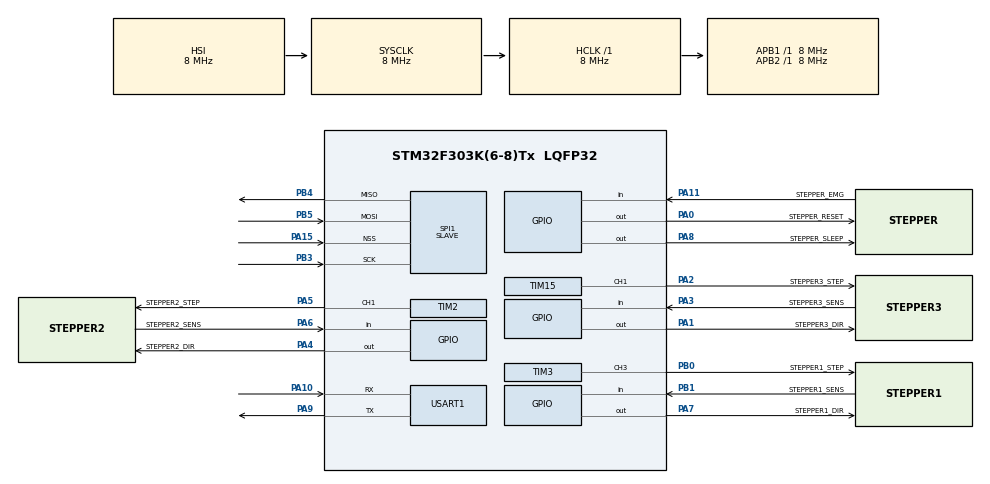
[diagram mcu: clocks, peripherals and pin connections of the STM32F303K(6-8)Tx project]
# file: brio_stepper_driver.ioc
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Dma.Request0=SPI1_RX
Dma.Request1=SPI1_TX
Dma.SPI1_RX.0.Direction=DMA_PERIPH_TO_MEMORY
Dma.SPI1_RX.0.Instance=DMA1_Channel2
Dma.SPI1_RX.0.MemDataAlignment=DMA_MDATAALIGN_BYTE
Dma.SPI1_RX.0.MemInc=DMA_MINC_ENABLE
Dma.SPI1_RX.0.Mode=DMA_NORMAL
Dma.SPI1_RX.0.PeriphDataAlignment=DMA_PDATAALIGN_BYTE
Dma.SPI1_RX.0.PeriphInc=DMA_PINC_DISABLE
Dma.SPI1_RX.0.Priority=DMA_PRIORITY_LOW
Dma.SPI1_TX.1.Direction=DMA_MEMORY_TO_PERIPH
Dma.SPI1_TX.1.Instance=DMA1_Channel3
Dma.SPI1_TX.1.MemDataAlignment=DMA_MDATAALIGN_BYTE
Dma.SPI1_TX.1.MemInc=DMA_MINC_ENABLE
Dma.SPI1_TX.1.Mode=DMA_NORMAL
Dma.SPI1_TX.1.PeriphDataAlignment=DMA_PDATAALIGN_BYTE
Dma.SPI1_TX.1.PeriphInc=DMA_PINC_DISABLE
Dma.SPI1_TX.1.Priority=DMA_PRIORITY_LOW
Mcu.Family=STM32F3
Mcu.Name=STM32F303K(6-8)Tx
Mcu.Package=LQFP32
NVIC.DMA1_Channel2_IRQn=true\:0\:0\:false\:false\:true\:false\:true\:true
NVIC.DMA1_Channel3_IRQn=true\:0\:0\:false\:false\:true\:false\:true\:true
NVIC.PriorityGroup=NVIC_PRIORITYGROUP_4
NVIC.TIM1_BRK_TIM15_IRQn=true\:0\:0\:false\:false\:true\:true\:true\:true
NVIC.TIM2_IRQn=true\:0\:0\:false\:false\:true\:true\:true\:true
NVIC.TIM3_IRQn=true\:0\:0\:false\:false\:true\:true\:true\:true
NVIC.TIM6_DAC1_IRQn=true\:0\:0\:false\:false\:true\:true\:true\:true
PA0.GPIO_Label=STEPPER_RESET
PA0.Signal=GPIO_Output
PA1.GPIO_Label=STEPPER3_DIR
PA1.Signal=GPIO_Output
PA10.Mode=Asynchronous
PA10.Signal=USART1_RX
PA11.GPIO_Label=STEPPER_EMG
PA11.GPIO_PuPd=GPIO_PULLDOWN
PA11.Signal=GPIO_Input
PA13.Mode=Serial_Wire
PA13.Signal=SYS_JTMS-SWDIO
PA14.Mode=Serial_Wire
PA14.Signal=SYS_JTCK-SWCLK
PA15.Mode=NSS_Signal_Hard_Input
PA15.Signal=SPI1_NSS
PA2.GPIO_Label=STEPPER3_STEP
PA2.Signal=S_TIM15_CH1
PA3.GPIO_Label=STEPPER3_SENS
PA3.Signal=GPIO_Input
PA4.GPIO_Label=STEPPER2_DIR
PA4.Signal=GPIO_Output
PA5.GPIO_Label=STEPPER2_STEP
PA5.Signal=S_TIM2_CH1_ETR
PA6.GPIO_Label=STEPPER2_SENS
PA6.Signal=GPIO_Input
PA7.GPIO_Label=STEPPER1_DIR
PA7.Signal=GPIO_Output
PA8.GPIO_Label=STEPPER_SLEEP
PA8.Signal=GPIO_Output
PA9.Mode=Asynchronous
PA9.Signal=USART1_TX
PB0.GPIO_Label=STEPPER1_STEP
PB0.Signal=S_TIM3_CH3
PB1.GPIO_Label=STEPPER1_SENS
PB1.Signal=GPIO_Input
PB3.Mode=Full_Duplex_Slave
PB3.Signal=SPI1_SCK
PB4.Mode=Full_Duplex_Slave
PB4.Signal=SPI1_MISO
PB5.Mode=Full_Duplex_Slave
PB5.Signal=SPI1_MOSI
PF0\ /\ OSC_IN.Mode=HSE-External-Oscillator
PF0\ /\ OSC_IN.Signal=RCC_OSC_IN
PF1\ /\ OSC_OUT.Mode=HSE-External-Oscillator
PF1\ /\ OSC_OUT.Signal=RCC_OSC_OUT
ProjectManager.HeapSize=0x200
ProjectManager.StackSize=0x400
ProjectManager.TargetToolchain=Makefile
RCC.AHBFreq_Value=8000000
RCC.APB1Freq_Value=8000000
RCC.APB2Freq_Value=8000000
RCC.CortexFreq_Value=8000000
RCC.HSE_VALUE=16000000
RCC.HSI_VALUE=8000000
RCC.PLLMUL=RCC_PLL_MUL4
RCC.SYSCLKFreq_VALUE=8000000
SH.S_TIM15_CH1.0=TIM15_CH1,PWM Generation1 CH1
SH.S_TIM2_CH1_ETR.0=TIM2_CH1,PWM Generation1 CH1
SH.S_TIM3_CH3.0=TIM3_CH3,PWM Generation3 CH3
SPI1.DataSize=SPI_DATASIZE_8BIT
SPI1.Direction=SPI_DIRECTION_2LINES
SPI1.Mode=SPI_MODE_SLAVE
SPI1.VirtualNSS=VM_NSSHARD
SPI1.VirtualType=VM_SLAVE
TIM15.AutoReloadPreload=TIM_AUTORELOAD_PRELOAD_ENABLE
TIM15.Channel-PWM\ Generation1\ CH1=TIM_CHANNEL_1
TIM2.AutoReloadPreload=TIM_AUTORELOAD_PRELOAD_ENABLE
TIM2.Channel-PWM\ Generation1\ CH1=TIM_CHANNEL_1
TIM2.Period=65535
TIM3.AutoReloadPreload=TIM_AUTORELOAD_PRELOAD_ENABLE
TIM3.Channel-PWM\ Generation3\ CH3=TIM_CHANNEL_3
TIM6.AutoReloadPreload=TIM_AUTORELOAD_PRELOAD_ENABLE
TIM6.Period=1000-1
TIM6.Prescaler=8-1
USART1.VirtualMode-Asynchronous=VM_ASYNC
VP_IWDG_VS_IWDG.Mode=IWDG_Activate
VP_TIM15_VS_ClockSourceINT.Mode=Internal
VP_TIM2_VS_ClockSourceINT.Mode=Internal
VP_TIM3_VS_ClockSourceINT.Mode=Internal
VP_TIM6_VS_ClockSourceINT.Mode=Enable_Timer
board=custom

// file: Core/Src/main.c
/* USER CODE BEGIN Header */
/**
  ******************************************************************************
  * @file           : main.c
  * @brief          : Main program body
  ******************************************************************************
  * @attention
  *
  * Copyright (c) 2023 STMicroelectronics.
  * All rights reserved.
  *
  * This software is licensed under terms that can be found in the LICENSE file
  * in the root directory of this software component.
  * If no LICENSE file comes with this software, it is provided AS-IS.
  *
  ******************************************************************************
  */
/* USER CODE END Header */
#include "main.h"
#include "dma.h"
#include "iwdg.h"
#include "spi.h"
#include "tim.h"
#include "usart.h"
#include "gpio.h"

/* USER CODE BEGIN Includes */
#include "app.h"
/* USER CODE END Includes */

void SystemClock_Config(void);

int main(void)
{

  /* MCU Configuration--------------------------------------------------------*/

  /* Reset of all peripherals, Initializes the Flash interface and the Systick. */
  HAL_Init();

  /* Configure the system clock */
  SystemClock_Config();

  /* Initialize all configured peripherals */
  MX_GPIO_Init();
  MX_DMA_Init();
  MX_SPI1_Init();
  MX_USART1_UART_Init();
  MX_TIM2_Init();
  MX_TIM3_Init();
  MX_TIM15_Init();
  MX_TIM6_Init();
  MX_IWDG_Init();

  /* Infinite loop */
  /* USER CODE BEGIN WHILE */

  while (1) {
    MainTask();
    /* USER CODE END WHILE */

  }
}

void SystemClock_Config(void)
{
  RCC_OscInitTypeDef RCC_OscInitStruct = {0};
  RCC_ClkInitTypeDef RCC_ClkInitStruct = {0};
  RCC_PeriphCLKInitTypeDef PeriphClkInit = {0};

  /** Initializes the RCC Oscillators according to the specified parameters
  * in the RCC_OscInitTypeDef structure.
  */
  RCC_OscInitStruct.OscillatorType = RCC_OSCILLATORTYPE_HSI|RCC_OSCILLATORTYPE_LSI;
  RCC_OscInitStruct.HSIState = RCC_HSI_ON;
  RCC_OscInitStruct.HSICalibrationValue = RCC_HSICALIBRATION_DEFAULT;
  RCC_OscInitStruct.LSIState = RCC_LSI_ON;
  RCC_OscInitStruct.PLL.PLLState = RCC_PLL_NONE;
  if (HAL_RCC_OscConfig(&RCC_OscInitStruct) != HAL_OK)
  {
    Error_Handler();
  }

  /** Initializes the CPU, AHB and APB buses clocks
  */
  RCC_ClkInitStruct.ClockType = RCC_CLOCKTYPE_HCLK|RCC_CLOCKTYPE_SYSCLK
                              |RCC_CLOCKTYPE_PCLK1|RCC_CLOCKTYPE_PCLK2;
  RCC_ClkInitStruct.SYSCLKSource = RCC_SYSCLKSOURCE_HSI;
  RCC_ClkInitStruct.AHBCLKDivider = RCC_SYSCLK_DIV1;
  RCC_ClkInitStruct.APB1CLKDivider = RCC_HCLK_DIV1;
  RCC_ClkInitStruct.APB2CLKDivider = RCC_HCLK_DIV1;

  if (HAL_RCC_ClockConfig(&RCC_ClkInitStruct, FLASH_LATENCY_0) != HAL_OK)
  {
    Error_Handler();
  }
  PeriphClkInit.PeriphClockSelection = RCC_PERIPHCLK_USART1;
  PeriphClkInit.Usart1ClockSelection = RCC_USART1CLKSOURCE_PCLK1;
  if (HAL_RCCEx_PeriphCLKConfig(&PeriphClkInit) != HAL_OK)
  {
    Error_Handler();
  }
}

void Error_Handler(void)
{
  __disable_irq();
  while (1)
  {
  }
}
